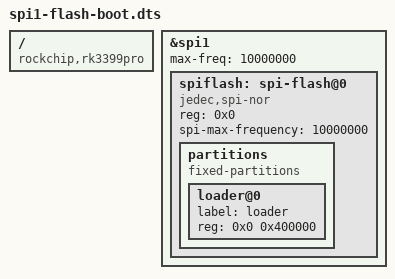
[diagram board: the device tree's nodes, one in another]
//This dtbo is used for booting ROCK Pi N10 from SPI Flash device.
//Test device: W25Q64FWIG
/dts-v1/;
/plugin/;

/ {
	compatible = "rockchip,rk3399pro";

	fragment@0 {
		target = <&spi1>;

		__overlay__ {
			status = "okay";
			max-freq = <10000000>;
			#address-cells = <1>;
			#size-cells = <0>;

			spiflash: spi-flash@0 {
				#address-cells = <0x1>;
				#size-cells = <1>;
				compatible = "jedec,spi-nor";
				reg = <0x0>;
				spi-max-frequency = <10000000>;
				status = "okay";

				partitions {
					compatible = "fixed-partitions";
					#address-cells = <1>;
					#size-cells = <1>;

					loader@0 {
						label = "loader";
						reg = <0x0 0x400000>;
					};
				};
			};
		};
	};
};
